VERSION ""

NS_ :

BS_:

BU_: PAS DIAG KLIMA SCCM PSM DME
VAL_TABLE_ Drive_Modes 34976 "SportPlus (Lights On)" 32928 "SportPlus (Lights Off)" 2208 "Sport (Lights On)" 2176 "Both Off (Lights On)" 160 "Sport (Lights Off)" 8 "Both Off (Lights Off)" ;
VAL_TABLE_ PASM 179 "PASM = SPORT" 162 "PASM = SOFT" ;
VAL_TABLE_ PAS_KeyPosition 2 "Engine Start" 1 "Ignition On" 0 "Ignition Off" ;

BO_ 3221225472 VECTOR__INDEPENDENT_SIG_MSG: 0 Vector__XXX
 SG_ DME4_B7 : 0|8@1+ (1,0) [0|0] "" Vector__XXX
 SG_ DME_MUX2 : 0|8@1+ (1,0) [0|0] "" Vector__XXX

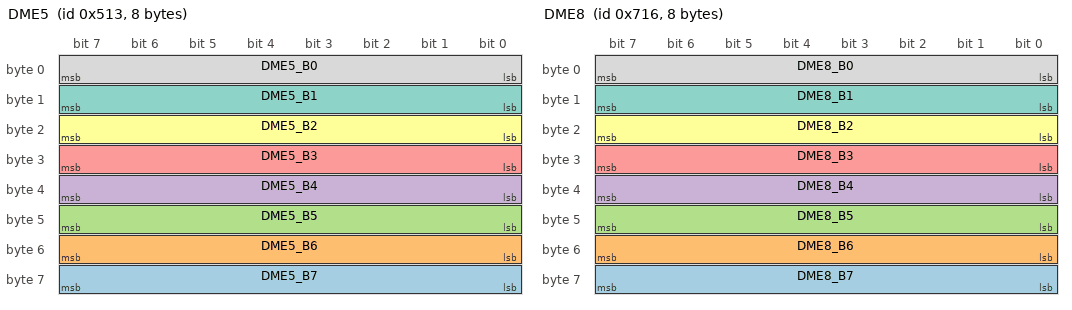
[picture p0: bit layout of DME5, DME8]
BO_ 1299 DME5: 8 Vector__XXX
 SG_ DME5_B7 : 56|8@1+ (1,0) [0|255] "" Vector__XXX
 SG_ DME5_B6 : 48|8@1+ (1,0) [0|255] "" Vector__XXX
 SG_ DME5_B5 : 40|8@1+ (1,0) [0|255] "" Vector__XXX
 SG_ DME5_B4 : 32|8@1+ (1,0) [0|255] "" Vector__XXX
 SG_ DME5_B3 : 24|8@1+ (1,0) [0|255] "" Vector__XXX
 SG_ DME5_B2 : 16|8@1+ (1,0) [0|255] "" Vector__XXX
 SG_ DME5_B1 : 8|8@1+ (1,0) [0|255] "" Vector__XXX
 SG_ DME5_B0 : 0|8@1+ (1,0) [0|255] "" Vector__XXX

BO_ 776 DRIVEMODE: 2 Vector__XXX
 SG_ Drive_Mode : 0|16@1+ (1,0) [0|65535] "" Vector__XXX

BO_ 1090 PASM: 1 Vector__XXX
 SG_ PASM_Setting_Request : 0|8@1+ (1,0) [0|255] "" Vector__XXX

BO_ 320 Airbag: 8 Vector__XXX

BO_ 1814 DME8: 8 Vector__XXX
 SG_ DME8_B7 : 56|8@1+ (1,0) [0|255] "" Vector__XXX
 SG_ DME8_B6 : 48|8@1+ (1,0) [0|255] "" Vector__XXX
 SG_ DME8_B5 : 40|8@1+ (1,0) [0|255] "" Vector__XXX
 SG_ DME8_B4 : 32|8@1+ (1,0) [0|255] "" Vector__XXX
 SG_ DME8_B3 : 24|8@1+ (1,0) [0|255] "" Vector__XXX
 SG_ DME8_B2 : 16|8@1+ (1,0) [0|255] "" Vector__XXX
 SG_ DME8_B1 : 8|8@1+ (1,0) [0|255] "" Vector__XXX
 SG_ DME8_B0 : 0|8@1+ (1,0) [0|255] "" Vector__XXX

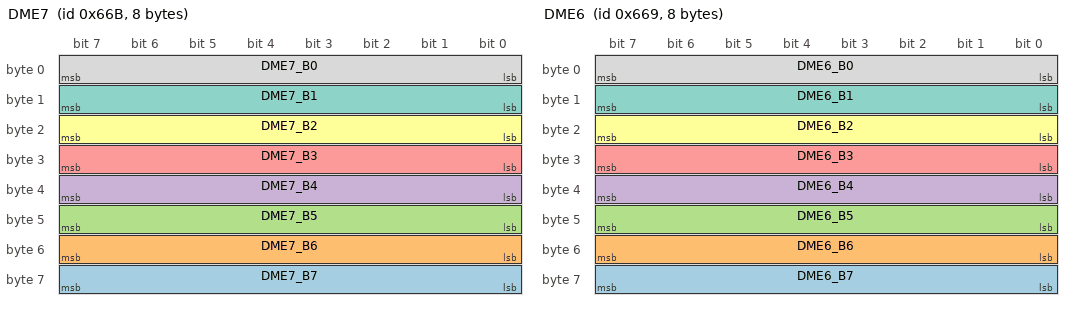
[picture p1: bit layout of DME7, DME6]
BO_ 1643 DME7: 8 Vector__XXX
 SG_ DME7_B7 : 56|8@1+ (1,0) [0|255] "" Vector__XXX
 SG_ DME7_B6 : 48|8@1+ (1,0) [0|255] "" Vector__XXX
 SG_ DME7_B5 : 40|8@1+ (1,0) [0|255] "" Vector__XXX
 SG_ DME7_B4 : 32|8@1+ (1,0) [0|255] "" Vector__XXX
 SG_ DME7_B3 : 24|8@1+ (1,0) [0|255] "" Vector__XXX
 SG_ DME7_B2 : 16|8@1+ (1,0) [0|255] "" Vector__XXX
 SG_ DME7_B1 : 8|8@1+ (1,0) [0|255] "" Vector__XXX
 SG_ DME7_B0 : 0|8@1+ (1,0) [0|255] "" Vector__XXX

BO_ 1641 DME6: 8 Vector__XXX
 SG_ DME6_B7 : 56|8@1+ (1,0) [0|255] "" Vector__XXX
 SG_ DME6_B6 : 48|8@1+ (1,0) [0|255] "" Vector__XXX
 SG_ DME6_B5 : 40|8@1+ (1,0) [0|255] "" Vector__XXX
 SG_ DME6_B4 : 32|8@1+ (1,0) [0|255] "" Vector__XXX
 SG_ DME6_B3 : 24|8@1+ (1,0) [0|255] "" Vector__XXX
 SG_ DME6_B2 : 16|8@1+ (1,0) [0|255] "" Vector__XXX
 SG_ DME6_B1 : 8|8@1+ (1,0) [0|255] "" Vector__XXX
 SG_ DME6_B0 : 0|8@1+ (1,0) [0|255] "" Vector__XXX

BO_ 1816 PSM5: 8 Vector__XXX

BO_ 1818 SCCM3: 8 Vector__XXX

BO_ 1098 PSM3: 8 Vector__XXX

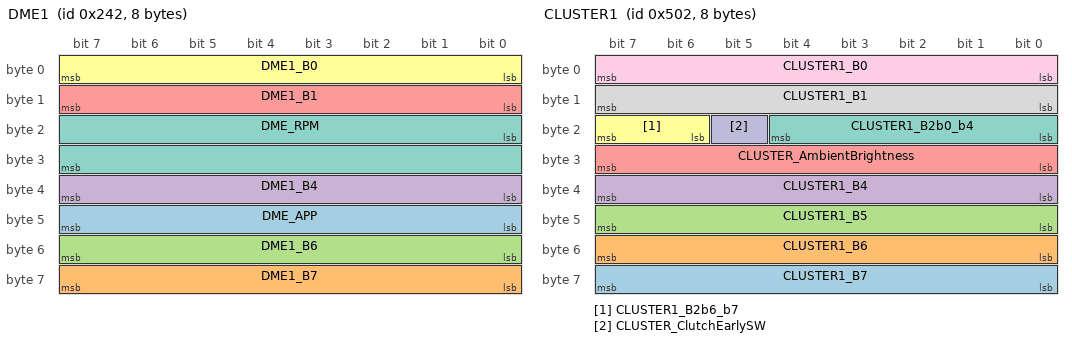
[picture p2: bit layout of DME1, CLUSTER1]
BO_ 578 DME1: 8 Vector__XXX
 SG_ DME_APP : 40|8@1+ (0.39215,0) [0|99.99825] "%" Vector__XXX
 SG_ DME1_B7 : 56|8@1+ (1,0) [0|0] "" Vector__XXX
 SG_ DME1_B6 : 48|8@1+ (1,0) [0|0] "" Vector__XXX
 SG_ DME1_B4 : 32|8@1+ (1,0) [0|0] "" Vector__XXX
 SG_ DME1_B1 : 8|8@1+ (1,0) [0|0] "%" Vector__XXX
 SG_ DME1_B0 : 0|8@1+ (1,0) [0|0] "" Vector__XXX
 SG_ DME_RPM : 16|16@1+ (0.25,0) [0|0] "rpm" Vector__XXX

BO_ 1282 CLUSTER1: 8 Vector__XXX
 SG_ CLUSTER1_B7 : 56|8@1+ (1,0) [0|0] "" Vector__XXX
 SG_ CLUSTER1_B6 : 48|8@1+ (1,0) [0|0] "" Vector__XXX
 SG_ CLUSTER1_B5 : 40|8@1+ (1,0) [0|0] "" Vector__XXX
 SG_ CLUSTER1_B4 : 32|8@1+ (1,0) [0|0] "" Vector__XXX
 SG_ CLUSTER_AmbientBrightness : 24|8@1+ (0.3922,0) [0|0] "%" Vector__XXX
 SG_ CLUSTER1_B2b6_b7 : 22|2@1+ (1,0) [0|0] "" Vector__XXX
 SG_ CLUSTER1_B2b0_b4 : 16|5@1+ (1,0) [0|0] "" Vector__XXX
 SG_ CLUSTER1_B1 : 8|8@1+ (1,0) [0|0] "" Vector__XXX
 SG_ CLUSTER1_B0 : 0|8@1+ (1,0) [0|0] "" Vector__XXX
 SG_ CLUSTER_ClutchEarlySW : 21|1@1+ (1,0) [0|0] "" Vector__XXX

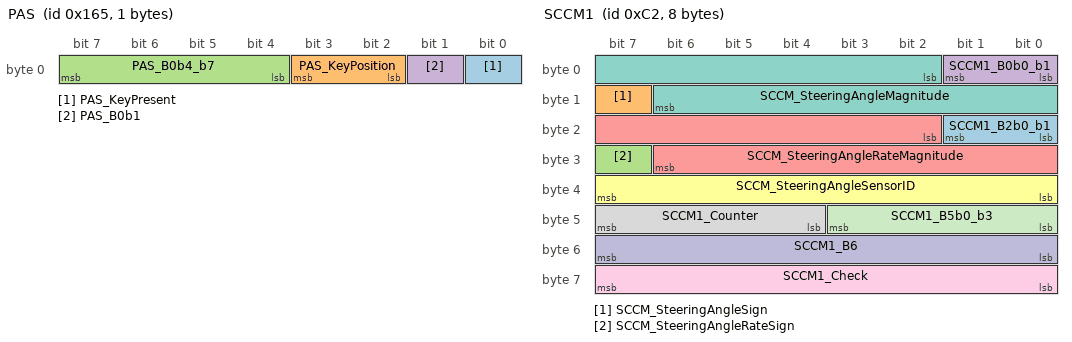
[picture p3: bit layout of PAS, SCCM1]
BO_ 357 PAS: 1 PAS
 SG_ PAS_KeyPresent : 0|1@1+ (1,0) [0|0] "" Vector__XXX
 SG_ PAS_KeyPosition : 2|2@1+ (1,0) [0|0] "" Vector__XXX
 SG_ PAS_B0b4_b7 : 4|4@1+ (1,0) [0|0] "" Vector__XXX
 SG_ PAS_B0b1 : 1|1@1+ (1,0) [0|0] "" Vector__XXX

BO_ 194 SCCM1: 8 SCCM
 SG_ SCCM1_B2b0_b1 : 16|2@1+ (1,0) [0|0] "" Vector__XXX
 SG_ SCCM_SteeringAngleSign : 15|1@1+ (1,0) [0|0] "" Vector__XXX
 SG_ SCCM_SteeringAngleRateSign : 31|1@1+ (1,0) [0|0] "" Vector__XXX
 SG_ SCCM1_B0b0_b1 : 0|2@1+ (1,0) [0|0] "" Vector__XXX
 SG_ SCCM_SteeringAngleRateMagnitude : 18|13@1+ (0.175,0) [0|0] "deg/sec" Vector__XXX
 SG_ SCCM_SteeringAngleSensorID : 32|8@1+ (1,0) [0|0] "" Vector__XXX
 SG_ SCCM_SteeringAngleMagnitude : 2|13@1+ (0.175,0) [0|0] "deg" Vector__XXX
 SG_ SCCM1_Counter : 44|4@1+ (1,0) [0|0] "" Vector__XXX
 SG_ SCCM1_Check : 56|8@1+ (1,0) [0|0] "" Vector__XXX
 SG_ SCCM1_B6 : 48|8@1+ (1,0) [0|0] "" Vector__XXX
 SG_ SCCM1_B5b0_b3 : 40|4@1+ (1,0) [0|0] "" Vector__XXX

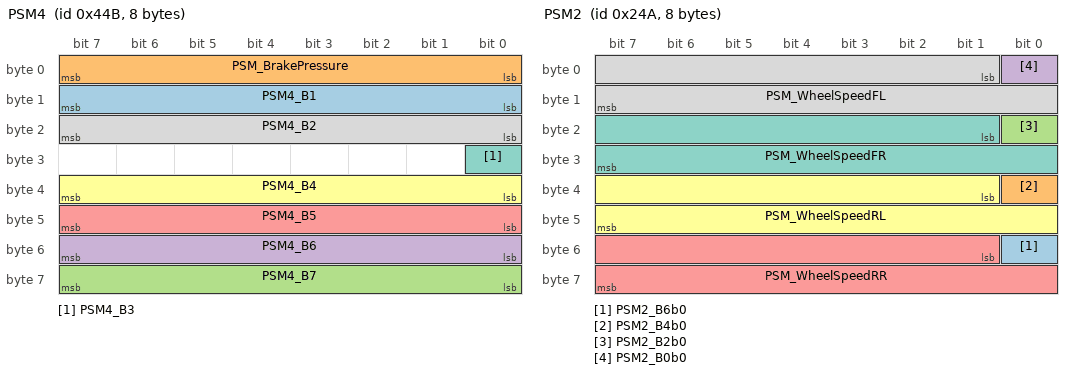
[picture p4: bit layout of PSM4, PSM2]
BO_ 1099 PSM4: 8 PSM
 SG_ PSM4_B1 : 8|8@1+ (1,0) [0|0] "" Vector__XXX
 SG_ PSM_BrakePressure : 0|8@1+ (1,0) [0|0] "Bar" Vector__XXX
 SG_ PSM4_B7 : 56|8@1+ (1,0) [0|0] "" Vector__XXX
 SG_ PSM4_B6 : 48|8@1+ (1,0) [0|0] "" Vector__XXX
 SG_ PSM4_B5 : 40|8@1+ (1,0) [0|0] "" Vector__XXX
 SG_ PSM4_B4 : 32|8@1+ (1,0) [0|0] "" Vector__XXX
 SG_ PSM4_B3 : 24|1@1+ (1,0) [0|0] "" Vector__XXX
 SG_ PSM4_B2 : 16|8@1+ (1,0) [0|0] "" Vector__XXX

BO_ 586 PSM2: 8 PSM
 SG_ PSM2_B6b0 : 48|1@1+ (1,0) [0|0] "" Vector__XXX
 SG_ PSM2_B4b0 : 32|1@1+ (1,0) [0|0] "" Vector__XXX
 SG_ PSM2_B2b0 : 16|1@1+ (1,0) [0|0] "" Vector__XXX
 SG_ PSM2_B0b0 : 0|1@1+ (1,0) [0|0] "" Vector__XXX
 SG_ PSM_WheelSpeedRR : 49|15@1+ (0.02,0) [0|0] "km/h" Vector__XXX
 SG_ PSM_WheelSpeedRL : 33|15@1+ (0.02,0) [0|0] "km/h" Vector__XXX
 SG_ PSM_WheelSpeedFR : 17|15@1+ (0.02,0) [0|0] "km/h" Vector__XXX
 SG_ PSM_WheelSpeedFL : 1|15@1+ (0.02,0) [0|0] "km/h" Vector__XXX

BO_ 330 PSM1: 8 PSM
 SG_ PSM1_B1b6 : 14|1@1+ (1,0) [0|0] "" Vector__XXX
 SG_ PSM1_B0b2_b3 : 2|2@1+ (1,0) [0|0] "" Vector__XXX
 SG_ PSM1_B0b0 : 0|1@1+ (1,0) [0|0] "" Vector__XXX
 SG_ PSM_FootBrake2 : 12|1@1+ (1,0) [0|0] "" Vector__XXX
 SG_ PSM1_Counter : 48|8@1+ (1,0) [0|0] "" Vector__XXX
 SG_ PSM1_B3 : 24|8@1+ (1,0) [0|0] "" Vector__XXX
 SG_ PSM1_B2 : 16|8@1+ (1,0) [0|0] "" Vector__XXX
 SG_ PSM1_B1b0_b2 : 8|3@1+ (1,0) [0|0] "" Vector__XXX
 SG_ PSM1_B0b5_b7 : 5|3@1+ (1,0) [0|0] "" Vector__XXX
 SG_ PSM_TorqueRequestSlow : 32|8@1+ (1,0) [0|0] "" Vector__XXX
 SG_ PSM_TorqueRequestFast : 40|8@1+ (1,0) [0|0] "" Vector__XXX
 SG_ PSM_LateralAccel : 56|8@1+ (1,0) [0|0] "" Vector__XXX
 SG_ PSM_HandBrake : 15|1@1+ (1,0) [0|0] "" Vector__XXX
 SG_ PSM_FootBrake : 11|1@1+ (1,0) [0|0] "" Vector__XXX
 SG_ PSM_ESPintervention : 4|1@1+ (1,0) [0|0] "" Vector__XXX
 SG_ PSM_Disabled : 13|1@1+ (1,0) [0|0] "" Vector__XXX
 SG_ PSM_ABSactive : 1|1@1+ (1,0) [0|0] "" Vector__XXX

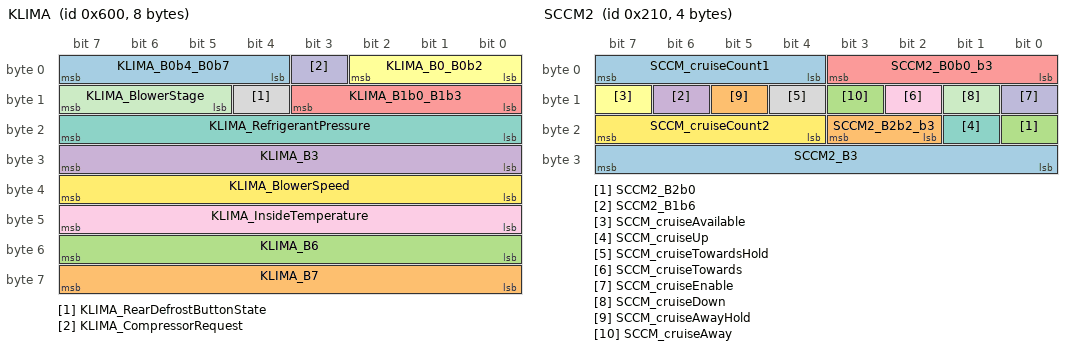
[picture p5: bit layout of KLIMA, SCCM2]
BO_ 1536 KLIMA: 8 KLIMA
 SG_ KLIMA_B0b4_B0b7 : 4|4@1+ (1,0) [0|0] "" Vector__XXX
 SG_ KLIMA_B7 : 56|8@1+ (1,0) [0|0] ""  DIAG
 SG_ KLIMA_B6 : 48|8@1+ (1,0) [0|0] ""  DIAG
 SG_ KLIMA_B3 : 24|8@1+ (1,0) [0|0] ""  DIAG
 SG_ KLIMA_B1b0_B1b3 : 8|4@1+ (1,0) [0|0] ""  DIAG
 SG_ KLIMA_B0_B0b2 : 0|3@1+ (1,0) [0|0] ""  DIAG
 SG_ KLIMA_RefrigerantPressure : 16|8@1+ (0.2,0) [0|51] "Bar"  DIAG
 SG_ KLIMA_RearDefrostButtonState : 12|1@1+ (1,0) [0|0] ""  DIAG
 SG_ KLIMA_InsideTemperature : 40|8@1+ (0.5,-50) [-50|77.5] "C"  DIAG
 SG_ KLIMA_CompressorRequest : 3|1@1+ (1,0) [0|0] ""  DIAG
 SG_ KLIMA_BlowerStage : 13|3@1+ (1,0) [0|7] ""  DIAG
 SG_ KLIMA_BlowerSpeed : 32|8@1+ (1,0) [0|255] ""  DIAG

BO_ 528 SCCM2: 4 SCCM
 SG_ SCCM2_B3 : 24|8@1+ (1,0) [0|0] "" Vector__XXX
 SG_ SCCM2_B2b2_b3 : 18|2@1+ (1,0) [0|0] "" Vector__XXX
 SG_ SCCM2_B2b0 : 16|1@1+ (1,0) [0|0] "" Vector__XXX
 SG_ SCCM2_B1b6 : 14|1@1+ (1,0) [0|0] "" Vector__XXX
 SG_ SCCM2_B0b0_b3 : 0|4@1+ (1,0) [0|0] "" Vector__XXX
 SG_ SCCM_cruiseAvailable : 15|1@1+ (1,0) [0|0] ""  DIAG
 SG_ SCCM_cruiseUp : 17|1@1+ (1,0) [0|0] ""  DIAG
 SG_ SCCM_cruiseTowardsHold : 12|1@1+ (1,0) [0|0] ""  DIAG
 SG_ SCCM_cruiseTowards : 10|1@1+ (1,0) [0|0] ""  DIAG
 SG_ SCCM_cruiseEnable : 8|1@1+ (1,0) [0|0] ""  DIAG
 SG_ SCCM_cruiseDown : 9|1@1+ (1,0) [0|0] ""  DIAG
 SG_ SCCM_cruiseCount2 : 20|4@1+ (1,0) [0|0] ""  DIAG
 SG_ SCCM_cruiseCount1 : 4|4@1+ (1,0) [0|0] ""  DIAG
 SG_ SCCM_cruiseAwayHold : 13|1@1+ (1,0) [0|0] ""  DIAG
 SG_ SCCM_cruiseAway : 11|1@1+ (1,0) [0|0] ""  DIAG

BO_ 1089 DME4: 8 DME
 SG_ DME4_EngineComp_TempSensFaill : 63|1@1+ (1,0) [0|0] "" Vector__XXX
 SG_ DME4_Engine_Compartment_Temp : 57|6@1- (1,-48) [0|0] "°C" Vector__XXX
 SG_ DME4_Coolant_Level_Switch : 56|1@1- (1,0) [0|0] "" Vector__XXX
 SG_ Oil_Pressure : 48|8@1+ (0.04,0) [0|10.2] "bar" Vector__XXX
 SG_ DME4_B2 : 16|8@1+ (1,0) [0|0] "" Vector__XXX
 SG_ DME_RaiatorFanSpeedReq : 8|7@1+ (1,0) [0|127] "%"  DIAG
 SG_ DME_EngineRunning : 15|1@1+ (1,0) [0|0] ""  DIAG
 SG_ DME_ALERT_ReducedPower : 3|1@1+ (1,0) [0|0] ""  DIAG
 SG_ DME_ALERT_OilTempSensorFailure : 5|1@1+ (1,0) [0|0] ""  DIAG
 SG_ DME_ALERT_OilPressure : 6|1@1+ (1,0) [0|0] ""  DIAG
 SG_ DME_ALERT_FuelReserve : 2|1@1+ (1,0) [0|0] ""  DIAG
 SG_ DME_ALERT_EngineCompartmentFan : 4|1@1+ (1,0) [0|0] ""  DIAG
 SG_ DME_ALERT_chargingSystem : 7|1@1+ (1,0) [0|0] ""  DIAG
 SG_ DME_ALERT_CEL_Steady : 1|1@1+ (1,0) [0|0] ""  DIAG
 SG_ DME_ALERT_CEL_Flashing : 0|1@1+ (1,0) [0|0] ""  DIAG
 SG_ Counter3 : 24|8@1+ (1,0) [0|255] ""  DIAG
 SG_ DME4_B4 : 32|8@1+ (1,0) [0|0] ""  DIAG
 SG_ DME_OilTemp : 40|8@1+ (0.75,0) [0|0] "C"  DIAG

BO_ 582 DME3: 8 DME
 SG_ Channel_3 m3 : 56|8@1+ (1,0) [0|0] "" Vector__XXX
 SG_ Channel_2 m2 : 56|8@1+ (1,0) [0|0] "" Vector__XXX
 SG_ TPS m1 : 56|8@1+ (0.39215,0) [0|99.99825] "%" Vector__XXX
 SG_ Channel_0 m0 : 56|8@1+ (1,0) [0|0] "" Vector__XXX
 SG_ DME3_B0b6_b7 : 6|2@1+ (1,0) [0|0] "" Vector__XXX
 SG_ DME3_Trq_Actual : 32|8@1+ (0.39,0) [0|99.45] "%" Vector__XXX
 SG_ DME_KickdownActive : 3|1@1+ (1,0) [0|0] ""  DIAG
 SG_ DME_EngagedGear : 0|3@1+ (1,0) [0|7] ""  DIAG
 SG_ DME_CompressorRunning : 4|1@1+ (1,0) [0|0] ""  DIAG
 SG_ DME_CompressorFault : 5|1@1+ (1,0) [0|0] ""  DIAG
 SG_ Count2 M : 48|8@1+ (1,0) [0|0] ""  DIAG
 SG_ DME_APP_2 : 24|8@1+ (0.39215,0) [0|0] "%"  DIAG
 SG_ DME3_Ambient_Pressure : 40|8@1+ (5,0) [0|1275] "mbar"  DIAG
 SG_ Target_Trq : 16|8@1+ (0.39,0) [0|99.45] "%"  DIAG
 SG_ DME3_Gearbox_Trq_Request : 8|8@1+ (0.39215,0) [0|99.99825] "&"  DIAG

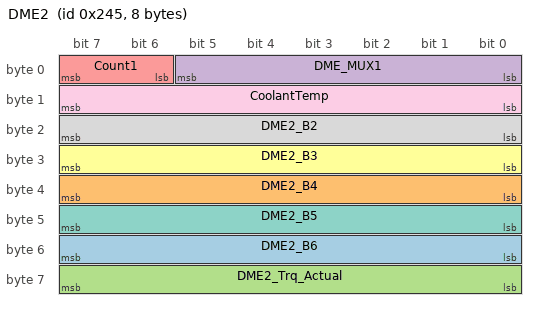
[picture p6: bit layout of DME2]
BO_ 581 DME2: 8 DME
 SG_ DME2_B6 : 48|8@1+ (1,0) [0|0] "" Vector__XXX
 SG_ DME2_B4 : 32|8@1+ (1,0) [0|0] "" Vector__XXX
 SG_ DME2_Trq_Actual : 56|8@1+ (0.39215,0) [0|99.99825] "%"  DIAG
 SG_ DME_MUX1 : 0|6@1+ (1,0) [0|0] ""  DIAG
 SG_ Count1 : 6|2@1+ (1,0) [0|0] ""  DIAG
 SG_ DME2_B3 : 24|8@1+ (1,0) [0|0] ""  DIAG
 SG_ DME2_B5 : 40|8@1+ (1,0) [0|0] ""  DIAG
 SG_ DME2_B2 : 16|8@1+ (1,0) [0|0] ""  DIAG
 SG_ CoolantTemp : 8|8@1+ (0.75,0) [0|0] "C"  DIAG

CM_ BO_ 3221225472 "This is a message for not used signals, created by Vector CANdb++ DBC OLE DB Provider.";
CM_ BO_ 1814 "1 Hz, This is the Motronic Software version

987 Coding: 
0= 0x18
1= 0x53
2= 0x22
3= 0x10
4=0
5=0
6=0
7=0



";
CM_ BO_ 1643 "1 Hz, Chassis number encoded as BCD and ASCII";
CM_ BO_ 1641 "1 Hz 

Country code, 0 for Germany, 16 for UK";
CM_ SG_ 578 DME1_B1 "TPS or APP";
CM_ SG_ 194 SCCM_SteeringAngleSign "1=Steering right
0=Steering left";
CM_ SG_ 194 SCCM_SteeringAngleRateSign "1=turning wheel CW
0=turning wheel CCW";
CM_ SG_ 1536 KLIMA_RefrigerantPressure "high side refrigerant pressure";
CM_ SG_ 1536 KLIMA_RearDefrostButtonState "this signal follows the immediate state of the rear defroster button on the climate control module. Its remains high while the button is pressed, and goes low when the button is released.";
CM_ SG_ 1536 KLIMA_InsideTemperature "cabin temperature as measured by the climate control unit";
CM_ SG_ 1536 KLIMA_CompressorRequest "this signal follows the immediate state of the rear defroster button on the climate control module. Its remains high while the button is pressed, and goes low when the button is released.";
CM_ SG_ 1536 KLIMA_BlowerStage "unknown units of blower speed

Display bars - Reported value (DEC)
0	0
1	0
2	1
3	1
4	1
5	2
6	2
7	2
8	3
9	3
10	3
11	4
12	4
13	4
14	5
15	5
16	5
17	6
18	6
19	6
";
CM_ SG_ 1536 KLIMA_BlowerSpeed "unknown units of blower speed

Display bars - Reported Value (DEC)
0	0
1	52
2	64
3	76
4	88
5	100
6	112
7	125
8	136
9	149
10	161
11	172
12	185
13	197
14	209
15	221
16	233
17	245
18	250
19	250
";
CM_ SG_ 1089 DME_RaiatorFanSpeedReq "fan speed request to front control module, response time varies and has been observed as high as 20s";
CM_ SG_ 1089 DME_EngineRunning "signal is present when the engine is running faster than 40 RPM
this cluster go into a bulb test mode when this bit is not set
unclear what other components in the vehicle a recievers of this signal";
CM_ SG_ 1089 DME_ALERT_ReducedPower "triggers cluster text: reduced engine power";
CM_ SG_ 1089 DME_ALERT_OilTempSensorFailure "triggers cluster text:";
CM_ SG_ 1089 DME_ALERT_OilPressure "triggers cluster text: engine oil pressure too low";
CM_ SG_ 1089 DME_ALERT_FuelReserve "triggers cluster flashing indicator at the bottom of the fuel level gauge";
CM_ SG_ 1089 DME_ALERT_EngineCompartmentFan "triggers cluster text: failure of engine compartment blower
triggers cluster flahsing light at top of coolant gauge scale";
CM_ SG_ 1089 DME_ALERT_chargingSystem "triggers cluster text: warning battery/generator";
CM_ SG_ 1089 DME_ALERT_CEL_Steady "triggers cluster text: check engine visit workshop
triggers cluster CEL light, stays on steady";
CM_ SG_ 1089 DME_ALERT_CEL_Flashing "triggers cluster text: check engine visit workshop
triggers cluster CEL light, flashes";
CM_ SG_ 1089 Counter3 "0-255";
CM_ SG_ 582 DME_KickdownActive "<not verified>";
CM_ SG_ 582 DME_EngagedGear "<not verified> - enumeration unknown";
CM_ SG_ 582 DME_CompressorRunning "signal is received by the climate control module, in PIWIS this signal is shown as: CAN compressor shutdown. setting this bit as 0=yes (compressor is not running), 1=no (compressor is running)";
CM_ SG_ 582 DME_CompressorFault "unclear who recieved this signal, its doesnt trigger an obvious response from climate control diagnostic parameters available in PIWIS";
CM_ SG_ 581 DME_MUX1 "Multiplexer 0 is reserved, 1 indicates engine type (below), 2 indicates gearbox type (below). 

Mux = 1
0=3.4L
1=3.2L
3=Turbo
4=2.7L
5=3.6L

Mux = 2
0=manual
1=automatic
2=CVTip";
BA_DEF_ SG_  "GenSigSendType" ENUM  "Cyclic","OnWrite","OnWriteWithRepetition","OnChange","OnChangeWithRepetition","IfActive","IfActiveWithRepetition","NoSigSendType";
BA_DEF_  "DBName" STRING ;
BA_DEF_ BO_  "GenMsgCycleTime" INT 0 0;
BA_DEF_ BO_  "GenMsgSendType" ENUM  "Cyclic","not_used","not_used","not_used","not_used","Cyclic","not_used","IfActive","NoMsgSendType";
BA_DEF_DEF_  "GenSigSendType" "Cyclic";
BA_DEF_DEF_  "DBName" "";
BA_DEF_DEF_  "GenMsgCycleTime" 0;
BA_DEF_DEF_  "GenMsgSendType" "NoMsgSendType";
BA_ "DBName" "____DRIVE_CAN";
BA_ "GenMsgSendType" BO_ 1282 0;
BA_ "GenMsgCycleTime" BO_ 1282 1000;
BA_ "GenMsgSendType" BO_ 357 0;
BA_ "GenMsgCycleTime" BO_ 357 200;
BA_ "GenMsgSendType" BO_ 194 0;
BA_ "GenMsgCycleTime" BO_ 194 10;
BA_ "GenMsgSendType" BO_ 1099 0;
BA_ "GenMsgCycleTime" BO_ 1099 10;
BA_ "GenMsgSendType" BO_ 586 0;
BA_ "GenMsgCycleTime" BO_ 586 20;
BA_ "GenMsgSendType" BO_ 330 0;
BA_ "GenMsgCycleTime" BO_ 330 20;
BA_ "GenMsgSendType" BO_ 1536 0;
BA_ "GenMsgCycleTime" BO_ 1536 100;
BA_ "GenMsgSendType" BO_ 528 0;
BA_ "GenMsgCycleTime" BO_ 528 20;
BA_ "GenMsgSendType" BO_ 1089 0;
BA_ "GenMsgCycleTime" BO_ 1089 20;
BA_ "GenMsgSendType" BO_ 582 0;
BA_ "GenMsgCycleTime" BO_ 582 10;
VAL_ 776 Drive_Mode 34976 "SportPlus (Lights On)" 32928 "SportPlus (Lights Off)" 2208 "Sport (Lights On)" 2176 "Both Off (Lights On)" 160 "Sport (Lights Off)" 8 "Both Off (Lights Off)" ;
VAL_ 1090 PASM_Setting_Request 179 "PASM = SPORT" 162 "PASM = SOFT" ;
VAL_ 357 PAS_KeyPosition 2 "Engine Start" 1 "Ignition On" 0 "Ignition Off" ;
